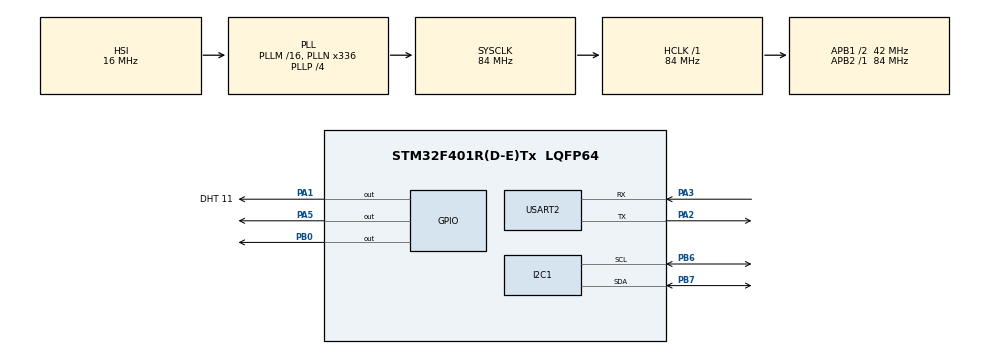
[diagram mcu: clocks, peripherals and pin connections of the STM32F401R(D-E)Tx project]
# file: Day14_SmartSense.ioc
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I2C1.I2C_Mode=I2C_Fast
IWDG.Prescaler=IWDG_PRESCALER_256
Mcu.Family=STM32F4
Mcu.Name=STM32F401R(D-E)Tx
Mcu.Package=LQFP64
NVIC.PriorityGroup=NVIC_PRIORITYGROUP_0
PA1.GPIO_Label=DHT 11
PA1.PinState=GPIO_PIN_SET
PA1.Signal=GPIO_Output
PA2.Mode=Asynchronous
PA2.Signal=USART2_TX
PA3.Mode=Asynchronous
PA3.Signal=USART2_RX
PA5.Signal=GPIO_Output
PB0.Signal=GPIO_Output
PB6.Mode=I2C
PB6.Signal=I2C1_SCL
PB7.Mode=I2C
PB7.Signal=I2C1_SDA
ProjectManager.HeapSize=0x200
ProjectManager.StackSize=0x400
ProjectManager.TargetToolchain=STM32CubeIDE
RCC.48MHZClocksFreq_Value=48000000
RCC.AHBFreq_Value=84000000
RCC.APB1CLKDivider=RCC_HCLK_DIV2
RCC.APB1Freq_Value=42000000
RCC.APB1TimFreq_Value=84000000
RCC.APB2Freq_Value=84000000
RCC.APB2TimFreq_Value=84000000
RCC.CortexFreq_Value=84000000
RCC.HCLKFreq_Value=84000000
RCC.HSE_VALUE=8000000
RCC.HSI_VALUE=16000000
RCC.PLLN=336
RCC.PLLP=RCC_PLLP_DIV4
RCC.PLLQ=7
RCC.SYSCLKFreq_VALUE=84000000
RCC.SYSCLKSource=RCC_SYSCLKSOURCE_PLLCLK
RCC.VCOOutputFreq_Value=336000000
USART2.VirtualMode=VM_ASYNC
VP_IWDG_VS_IWDG.Mode=IWDG_Activate
VP_TIM1_VS_ClockSourceINT.Mode=Internal
board=NUCLEO-F401RE

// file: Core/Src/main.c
/* USER CODE BEGIN Header */
/**
  ******************************************************************************
  * @file           : main.c
  * @brief          : Main program body
  ******************************************************************************
  * @attention
  *
  * Copyright (c) 2026 STMicroelectronics.
  * All rights reserved.
  *
  * This software is licensed under terms that can be found in the LICENSE file
  * in the root directory of this software component.
  * If no LICENSE file comes with this software, it is provided AS-IS.
  *
  ******************************************************************************
  */
/* USER CODE END Header */
#include "main.h"
#include "dht11.h"
#include "lcd.h"
#include <stdio.h>
#include <string.h>

I2C_HandleTypeDef hi2c1;

IWDG_HandleTypeDef hiwdg;

TIM_HandleTypeDef htim1;

UART_HandleTypeDef huart2;

/* USER CODE BEGIN PV */
DHT11_Data dhtData;
uint8_t watchdog_test = 1;
/* USER CODE END PV */

void SystemClock_Config(void);
static void MX_GPIO_Init(void);
static void MX_USART2_UART_Init(void);
static void MX_I2C1_Init(void);
static void MX_TIM1_Init(void);
static void MX_IWDG_Init(void);

int main(void)
{

  /* MCU Configuration--------------------------------------------------------*/

  /* Reset of all peripherals, Initializes the Flash interface and the Systick. */
  HAL_Init();

  /* Configure the system clock */
  SystemClock_Config();

  /* Initialize all configured peripherals */
  MX_GPIO_Init();
  MX_USART2_UART_Init();
  MX_I2C1_Init();
  MX_TIM1_Init();
  MX_IWDG_Init();
  /* USER CODE BEGIN 2 */
  HAL_TIM_Base_Start(&htim1);

  LCD_Init();
  LCD_Clear();

  LCD_SetCursor(0, 0);
  LCD_Print("DHT11 Testing");

  HAL_Delay(1000);
  LCD_Clear();

  /* USER CODE END 2 */

  /* Infinite loop */
  while (1)
  {

	    if (DHT11_Read(&dhtData))
	    {
	        char line1[17];
	        char line2[17];
	        char uart_msg[100];

	        sprintf(line1, "Temp: %d C", dhtData.temperature);

	        /* Temperature Alert Logic */
	        if (dhtData.temperature < 30)
	        {
	            sprintf(line2, "NORMAL");

	            HAL_GPIO_WritePin(GPIOA, GPIO_PIN_5, GPIO_PIN_RESET);
	            HAL_GPIO_WritePin(GPIOB, GPIO_PIN_0, GPIO_PIN_RESET);
	        }
	        else if (dhtData.temperature <= 35)
	        {
	            sprintf(line2, "WARNING");

	            HAL_GPIO_WritePin(GPIOA, GPIO_PIN_5, GPIO_PIN_SET);
	            HAL_GPIO_WritePin(GPIOB, GPIO_PIN_0, GPIO_PIN_SET);
	        }
	        else
	        {
	            sprintf(line2, "CRITICAL!");

	            HAL_GPIO_WritePin(GPIOA, GPIO_PIN_5, GPIO_PIN_SET);
	            HAL_GPIO_WritePin(GPIOB, GPIO_PIN_0, GPIO_PIN_SET);
	        }

	        /* UART Monitoring */
	        sprintf(uart_msg,
	                "Temperature: %d C | Humidity: %d %% | Status: %s\r\n",
	                dhtData.temperature,
	                dhtData.humidity,
	                (dhtData.temperature < 30) ? "NORMAL" :
	                (dhtData.temperature <= 35) ? "WARNING" :
	                "CRITICAL");

	        HAL_UART_Transmit(&huart2,
	                          (uint8_t *)uart_msg,
	                          strlen(uart_msg),
	                          HAL_MAX_DELAY);

	        /* LCD Display */
	        LCD_Clear();

	        LCD_SetCursor(0, 0);
	        LCD_Print(line1);

	        LCD_SetCursor(1, 0);
	        LCD_Print(line2);
	    }
	    else
	    {
	        /* DHT11 Sensor Error */

	        HAL_GPIO_WritePin(GPIOA, GPIO_PIN_5, GPIO_PIN_SET);
	        HAL_GPIO_WritePin(GPIOB, GPIO_PIN_0, GPIO_PIN_SET);

	        LCD_Clear();

	        LCD_SetCursor(0, 0);
	        LCD_Print("DHT11 ERROR");

	        LCD_SetCursor(1, 0);
	        LCD_Print("Sensor Failure");

	        /* UART Error Message */
	        char uart_error[] = "ERROR: DHT11 Sensor Failure\r\n";

	        HAL_UART_Transmit(&huart2,
	                          (uint8_t *)uart_error,
	                          strlen(uart_error),
	                          HAL_MAX_DELAY);
	    }

	    /* Refresh Independent Watchdog */
	    HAL_IWDG_Refresh(&hiwdg);

	    /* Watchdog Fault-Recovery Test */
	    if (watchdog_test)
	    {
	        while (1)
	        {
	            /* Simulated software hang */
	        }
	    }

	    /* DHT11 sampling interval */
	    HAL_Delay(2000);
	 }
  }

void SystemClock_Config(void)
{
  RCC_OscInitTypeDef RCC_OscInitStruct = {0};
  RCC_ClkInitTypeDef RCC_ClkInitStruct = {0};

  /** Configure the main internal regulator output voltage
  */
  __HAL_RCC_PWR_CLK_ENABLE();
  __HAL_PWR_VOLTAGESCALING_CONFIG(PWR_REGULATOR_VOLTAGE_SCALE2);

  /** Initializes the RCC Oscillators according to the specified parameters
  * in the RCC_OscInitTypeDef structure.
  */
  RCC_OscInitStruct.OscillatorType = RCC_OSCILLATORTYPE_HSI|RCC_OSCILLATORTYPE_LSI;
  RCC_OscInitStruct.HSIState = RCC_HSI_ON;
  RCC_OscInitStruct.HSICalibrationValue = RCC_HSICALIBRATION_DEFAULT;
  RCC_OscInitStruct.LSIState = RCC_LSI_ON;
  RCC_OscInitStruct.PLL.PLLState = RCC_PLL_ON;
  RCC_OscInitStruct.PLL.PLLSource = RCC_PLLSOURCE_HSI;
  RCC_OscInitStruct.PLL.PLLM = 16;
  RCC_OscInitStruct.PLL.PLLN = 336;
  RCC_OscInitStruct.PLL.PLLP = RCC_PLLP_DIV4;
  RCC_OscInitStruct.PLL.PLLQ = 7;
  if (HAL_RCC_OscConfig(&RCC_OscInitStruct) != HAL_OK)
  {
    Error_Handler();
  }

  /** Initializes the CPU, AHB and APB buses clocks
  */
  RCC_ClkInitStruct.ClockType = RCC_CLOCKTYPE_HCLK|RCC_CLOCKTYPE_SYSCLK
                              |RCC_CLOCKTYPE_PCLK1|RCC_CLOCKTYPE_PCLK2;
  RCC_ClkInitStruct.SYSCLKSource = RCC_SYSCLKSOURCE_PLLCLK;
  RCC_ClkInitStruct.AHBCLKDivider = RCC_SYSCLK_DIV1;
  RCC_ClkInitStruct.APB1CLKDivider = RCC_HCLK_DIV2;
  RCC_ClkInitStruct.APB2CLKDivider = RCC_HCLK_DIV1;

  if (HAL_RCC_ClockConfig(&RCC_ClkInitStruct, FLASH_LATENCY_2) != HAL_OK)
  {
    Error_Handler();
  }
}

static void MX_I2C1_Init(void)
{

  hi2c1.Instance = I2C1;
  hi2c1.Init.ClockSpeed = 100000;
  hi2c1.Init.DutyCycle = I2C_DUTYCYCLE_2;
  hi2c1.Init.OwnAddress1 = 0;
  hi2c1.Init.AddressingMode = I2C_ADDRESSINGMODE_7BIT;
  hi2c1.Init.DualAddressMode = I2C_DUALADDRESS_DISABLE;
  hi2c1.Init.OwnAddress2 = 0;
  hi2c1.Init.GeneralCallMode = I2C_GENERALCALL_DISABLE;
  hi2c1.Init.NoStretchMode = I2C_NOSTRETCH_DISABLE;
  if (HAL_I2C_Init(&hi2c1) != HAL_OK)
  {
    Error_Handler();
  }

}

static void MX_IWDG_Init(void)
{

  hiwdg.Instance = IWDG;
  hiwdg.Init.Prescaler = IWDG_PRESCALER_256;
  hiwdg.Init.Reload = 4095;
  if (HAL_IWDG_Init(&hiwdg) != HAL_OK)
  {
    Error_Handler();
  }

}

static void MX_TIM1_Init(void)
{

  TIM_ClockConfigTypeDef sClockSourceConfig = {0};
  TIM_MasterConfigTypeDef sMasterConfig = {0};

  htim1.Instance = TIM1;
  htim1.Init.Prescaler = 83;
  htim1.Init.CounterMode = TIM_COUNTERMODE_UP;
  htim1.Init.Period = 65535;
  htim1.Init.ClockDivision = TIM_CLOCKDIVISION_DIV1;
  htim1.Init.RepetitionCounter = 0;
  htim1.Init.AutoReloadPreload = TIM_AUTORELOAD_PRELOAD_DISABLE;
  if (HAL_TIM_Base_Init(&htim1) != HAL_OK)
  {
    Error_Handler();
  }
  sClockSourceConfig.ClockSource = TIM_CLOCKSOURCE_INTERNAL;
  if (HAL_TIM_ConfigClockSource(&htim1, &sClockSourceConfig) != HAL_OK)
  {
    Error_Handler();
  }
  sMasterConfig.MasterOutputTrigger = TIM_TRGO_RESET;
  sMasterConfig.MasterSlaveMode = TIM_MASTERSLAVEMODE_DISABLE;
  if (HAL_TIMEx_MasterConfigSynchronization(&htim1, &sMasterConfig) != HAL_OK)
  {
    Error_Handler();
  }

}

static void MX_USART2_UART_Init(void)
{

  huart2.Instance = USART2;
  huart2.Init.BaudRate = 115200;
  huart2.Init.WordLength = UART_WORDLENGTH_8B;
  huart2.Init.StopBits = UART_STOPBITS_1;
  huart2.Init.Parity = UART_PARITY_NONE;
  huart2.Init.Mode = UART_MODE_TX_RX;
  huart2.Init.HwFlowCtl = UART_HWCONTROL_NONE;
  huart2.Init.OverSampling = UART_OVERSAMPLING_16;
  if (HAL_UART_Init(&huart2) != HAL_OK)
  {
    Error_Handler();
  }

}

static void MX_GPIO_Init(void)
{
  GPIO_InitTypeDef GPIO_InitStruct = {0};

  /* GPIO Ports Clock Enable */
  __HAL_RCC_GPIOA_CLK_ENABLE();
  __HAL_RCC_GPIOB_CLK_ENABLE();

  /*Configure GPIO pin Output Level */
  HAL_GPIO_WritePin(DHT_11_GPIO_Port, DHT_11_Pin, GPIO_PIN_SET);

  /*Configure GPIO pin Output Level */
  HAL_GPIO_WritePin(GPIOA, GPIO_PIN_5, GPIO_PIN_RESET);

  /*Configure GPIO pin Output Level */
  HAL_GPIO_WritePin(GPIOB, GPIO_PIN_0, GPIO_PIN_RESET);

  /*Configure GPIO pins : DHT_11_Pin PA5 */
  GPIO_InitStruct.Pin = DHT_11_Pin|GPIO_PIN_5;
  GPIO_InitStruct.Mode = GPIO_MODE_OUTPUT_PP;
  GPIO_InitStruct.Pull = GPIO_NOPULL;
  GPIO_InitStruct.Speed = GPIO_SPEED_FREQ_LOW;
  HAL_GPIO_Init(GPIOA, &GPIO_InitStruct);

  /*Configure GPIO pin : PB0 */
  GPIO_InitStruct.Pin = GPIO_PIN_0;
  GPIO_InitStruct.Mode = GPIO_MODE_OUTPUT_PP;
  GPIO_InitStruct.Pull = GPIO_NOPULL;
  GPIO_InitStruct.Speed = GPIO_SPEED_FREQ_LOW;
  HAL_GPIO_Init(GPIOB, &GPIO_InitStruct);

}

void Error_Handler(void)
{
  __disable_irq();
  while (1)
  {
  }
}
